# MIMXRT685S_cm33 register map
Vendor: nxp.com; File version: 1.0
CPU: CM33 r2p0, little endian, MPU, FPU, VTOR, 3 interrupt priority bits
Registers are 32-bit, read-write, reset 0x0 unless marked. A register's access mark holds for its fields unless they carry their own. Offsets are from the block's base; [hi:lo] are bit positions; {n}, {i} and the like mark numbered series.

## PMC — LPC-Next0 Power Management Controller
Base 0x40135000
0x04 STATUS ro reset not defined — PMC status
  [0] ACTIVEFSM — General sequencer and finite state machine status
    0=All PMC finite state machines are idle. OK to set APPLYCFG to trigger the PMC state machines.; 1=One or more PMC finite state machines are active, do not set APPLYCFG or write to any PDRUNCFG or CTRL register values that are used by the PMC state machines
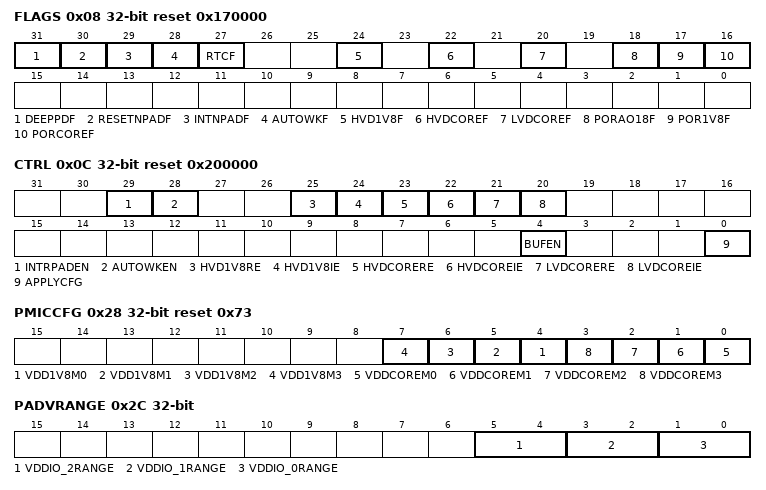
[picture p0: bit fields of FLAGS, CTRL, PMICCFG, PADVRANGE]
0x08 FLAGS reset 0x170000 — Wakeup, interrupt, and reset flags
  [31] DEEPPDF — Deep powerdown wakeup flag
    0=No deep powerdown wakeup since last time flag was cleared; 1=Deep powerdown was entered since the last time this flag was cleared. Write 1 to clear
  [30] RESETNPADF — Reset pad flag
    0=No reset detected since last time this flag was cleared; 1=Reset pad wakeup caused a wakeup or reset event since the last time this bit was cleared. Write 1 to clear.
  [29] INTNPADF — PMIC interrupt pin flag
    0=No interrupt detected since flag last cleared; 1=Pad interrupt caused a wakeup or interrupt event since the last time this flag was cleared. Write 1 to clear.
  [28] AUTOWKF — PMC Auto Wakeup Interrupt flag.
    0=No PMC Auto Wakeup Interrupt detected since last time cleared; 1=PMC Auto wakeup caused a deep sleep wakeup and interrupt. Write 1 to clear.
  [27] RTCF — RTC Wakeup from deep powerdown mode flag.
    0=No RTC wakeup detected since last time flag was cleared; 1=RTC wakeup caused a deep powerdown wakeup. Write 1 to clear.
  [24] HVD1V8F — vdd1v8 High-Voltage Detector Flag This flag is set when a high-voltage event was detected by the vdd1v8 HVD monitor and it is enabled for interrupt or reset
    0=vdd1v8 HVD has not triggered an interrupt or reset since last clear; 1=vdd1v8 HVD triggered an interrupt or reset since last time this bit was cleared. Write 1 to clear
  [22] HVDCOREF — vddcore High-Voltage Detector Flag This flag is set when a high-voltage event was detected by the vddcore HVD monitor and it is enabled for interrupt or reset
    0=vddcore HVD has not triggered an interrupt or reset since last clear; 1=vddcore HVD triggered an interrupt or reset since last time this bit was cleared. Write 1 to clear
  [20] LVDCOREF — vddcore Low-Voltage Detector Flag This flag is set when a low voltage event was detected by the vddcore LVD monitor and it is enabled for interrupt or reset
    0=vddcore LVD has not triggered an interrupt or reset since last clear; 1=vddcore LVD triggered an interrupt or reset since last time this bit was cleared. Write 1 to clear
  [18] PORAO18F — vdd_ao18 power on reset flag
    0=No vdd_ao18 power on event detected since last cleared; 1=vdd_ao18 power on detect caused a reset. Write 1 to clear.
  [17] POR1V8F — vdd1v8 power on reset flag
    0=No vdd1v8 power on event detected since last cleared; 1=vdd1v8 power on detect caused a reset or deep pd wakeup. Write 1 to clear.
  [16] PORCOREF — vddcore POR Flag
    0=vddcore POR was not tripped since the last cleared; 1=POR triggered by the vddcore POR monitor. Write 1 to clear
0x0C CTRL reset 0x200000 — PMC control register
  [29] INTRPADEN — PMIC interrupt pin enable
    0=Interrupt pad low has no effect; 1=Interrupt pad low triggers an interrupt and deep sleep wakeup or deep powerdown wakeup event
  [28] AUTOWKEN — PMC automatic wakeup enable and interrupt enable
    0=Auto wakeup interrupt and counter disabled; 1=Auto wakeup interrupt generated when PMC sequencer finishes and AUTOWAKE counter = 0 after entering deep sleep mode (but not deep powerdown mode). Interrupt will wake up the M33.
  [25] HVD1V8RE — vdd1v8 High-Voltage Detector Reset Enable
    0=vdd1v8 HVD reset disabled; 1=vdd1v8 HVD causes reset
  [24] HVD1V8IE — vdd1v8 High-Voltage Detector Interrupt Enable
    0=vdd1v8 HVD interrupt disabled; 1=vdd1v8 HVD causes interrupt and wakeup from deep sleep or deep power down mode
  [23] HVDCORERE — vddcore High-Voltage Detector Reset Enable
    0=vddcore HVD reset disabled; 1=vddcore HVD causes reset
  [22] HVDCOREIE — vddcore High-Voltage Detector Interrupt Enable
    0=vddcore HVD interrupt disabled; 1=vddcore HVD causes interrupt and wakeup from deep sleep
  [21] LVDCORERE — vddcore Low-Voltage Detector Reset Enable
    0=vddcore LVD reset disabled; 1=vddcore LVD causes reset
  [20] LVDCOREIE — vddcore Low-Voltage Detector Interrupt Enable
    0=vddcore LVD interrupt disabled; 1=vddcore LVD causes interrupt and wakeup from deep sleep
  [4] BUFEN — Enable analog buffer for references or ATX2
    0=disabled; 1=enabled
  [0] APPLYCFG — Apply updated PMC PDRUNCFG bits (SRAM power gates, RBB, FBB, LVD, and HVD control bits) and/or RUNCTRL setting
    0=Always reads 0. Write 0 has no effect; 1=Write 1 = initiate update sequencing of PMC state machines
0x10 RUNCTRL reset 0x21 — PMC controls used during run mode
  [5:0] CORELVL — Vddcore voltage value when SYSCTL is in run mode
0x14 SLEEPCTRL reset 0x21 — PMC controls used during deep sleep mode
  [5:0] CORELVL — Vddcore voltage value when SYSCTL is in sleep mode
0x18 LVDCORECTRL — Active vddcore LVD monitor trip adjust
  [3:0] LVDCORELVL — Vddcore LVD falling trip voltage
0x24 AUTOWKUP — Automatic wakeup from deepsleep / deep powerdown modes
  [15:0] AUTOWKTIME — Auto wake up delay timer. Added delay after sequencer delay value: delay time = value/16MHz
0x28 PMICCFG reset 0x73 — PMIC power mode select control configuration to let PMC know when vddcore or vdd1v8 will power off/on
  [all] fields
    0=off; 1=powered
  [n+4] VDD1V8M{n} (n=0..3) — vdd1v8 state in PMIC mode {n}
  [n] VDDCOREM{n} (n=0..3) — vddcore state in PMIC mode {n}
0x2C PADVRANGE — GPIO vdde range selection control
  [5:4] VDDIO_2RANGE
    0=1.71 - 3.6V. Consumes static current to detect VDDE2 level; 1=1.71 - 1.98V, vdde detector off; 2=3.00 - 3.6V, vdde detector off; 3=Not allowed (hardware should translate to 10)
  [3:2] VDDIO_1RANGE
    0=1.71-3.6V. Consumes static current to detect VDDE1 level; 1=1.71 - 1.98V, vdde detector off; 2=3.00 - 3.6V, vdde detector off; 3=Not allowed (hardware should translate to 10)
  [1:0] VDDIO_0RANGE
    0=1.71 - 3.6V. Consumes static current to detect VDDE0 level; 1=1.71 - 1.98V, vdde detector off; 2=3.00 - 3.6V, vdde detector off; 3=Not allowed (hardware should translate to 10)
0x30 MEMSEQCTRL reset 0x3F — Memory Sequencer Control Register
  [5:0] MEMSEQNUM — Number of memories to turn on/off at a time.
